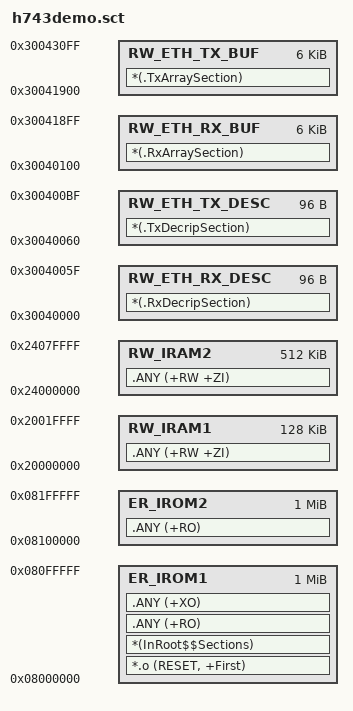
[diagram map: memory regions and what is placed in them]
; *************************************************************
; *** Scatter-Loading Description File generated by uVision ***
; *************************************************************

LR_IROM1 0x08000000 0x00100000  {    ; load region size_region
  ER_IROM1 0x08000000 0x00100000  {  ; load address = execution address
   *.o (RESET, +First)
   *(InRoot$$Sections)
   .ANY (+RO)
   .ANY (+XO)
  }
  RW_IRAM1 0x20000000 0x00020000  {  ; RW data
   .ANY (+RW +ZI)
  }
  RW_IRAM2 0x24000000 0x00080000  {
   .ANY (+RW +ZI)
  }
  RW_ETH_RX_DESC 0x30040000 0x00000060 {
   *(.RxDecripSection)
  }
  RW_ETH_TX_DESC 0x30040060 0x00000060 {
   *(.TxDecripSection)
  }
  RW_ETH_RX_BUF  0x30040100 0x00001800 {
   *(.RxArraySection)
  }
  RW_ETH_TX_BUF  0x30041900 0x00001800 {
   *(.TxArraySection)
  }
}

LR_IROM2 0x08100000 0x00100000  {
  ER_IROM2 0x08100000 0x00100000  {  ; load address = execution address
   .ANY (+RO)
  }
}
